# LPC43xx register map
File version: 10
CPU: CM4 r0p0, little endian, no MPU, no FPU, 3 interrupt priority bits
Registers are 32-bit, read-write, reset 0x0 unless marked. A register's access mark holds for its fields unless they carry their own. Offsets are from the block's base; [hi:lo] are bit positions; {n}, {i} and the like mark numbered series; 'fields as' and 'values as' point back to an identical list.

## RGU — Reset Generation Unit (RGU)
Base 0x40053000
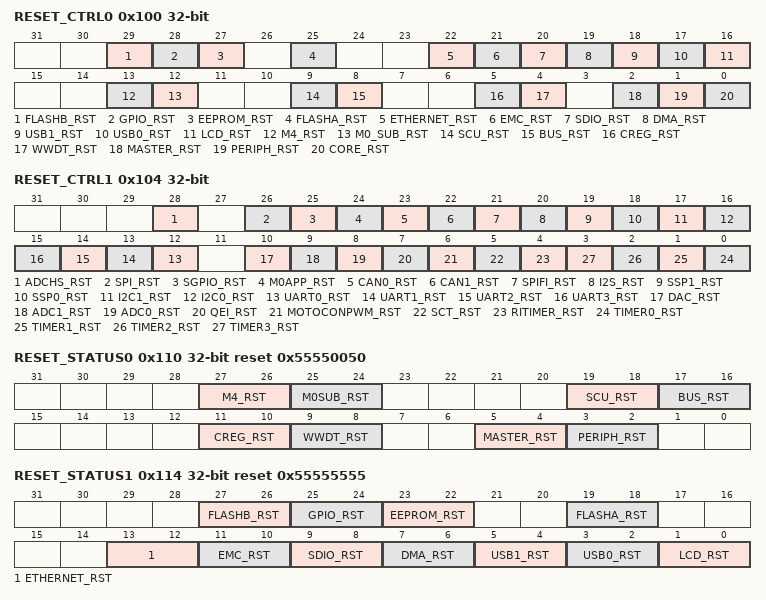
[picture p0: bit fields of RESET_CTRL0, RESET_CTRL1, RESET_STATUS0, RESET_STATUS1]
0x100 RESET_CTRL0 wo reset not defined — Reset control register 0
  [29] FLASHB_RST — Writing a one activates the reset. This bit is automatically cleared to 0 after one clock cycle.
  [28] GPIO_RST — Writing a one activates the reset. This bit is automatically cleared to 0 after one clock cycle.
  [27] EEPROM_RST — Writing a one activates the reset. This bit is automatically cleared to 0 after one clock cycle.
  [25] FLASHA_RST — Writing a one activates the reset. This bit is automatically cleared to 0 after one clock cycle.
  [22] ETHERNET_RST — Writing a one activates the reset. This bit is automatically cleared to 0 after one clock cycle.
  [21] EMC_RST — Writing a one activates the reset. This bit is automatically cleared to 0 after one clock cycle.
  [20] SDIO_RST — Writing a one activates the reset. This bit is automatically cleared to 0 after one clock cycle.
  [19] DMA_RST — Writing a one activates the reset. This bit is automatically cleared to 0 after one clock cycle.
  [18] USB1_RST — Writing a one activates the reset. This bit is automatically cleared to 0 after one clock cycle.
  [17] USB0_RST — Writing a one activates the reset. This bit is automatically cleared to 0 after one clock cycle.
  [16] LCD_RST — Writing a one activates the reset. This bit is automatically cleared to 0 after one clock cycle.
  [13] M4_RST — Writing a one activates the reset. This bit is automatically cleared to 0 after one clock cycle.
  [12] M0_SUB_RST — Writing a one activates the reset. Writing a 0 clears the reset. This bit must be cleared by software.
  [9] SCU_RST — Writing a one activates the reset. This bit is automatically cleared to 0 after one clock cycle.
  [8] BUS_RST — Writing a one activates the reset. This bit is automatically cleared to 0 after one clock cycle. Do not use during normal operation
  [5] CREG_RST — Writing a one to this bit has no effect.
  [4] WWDT_RST — Writing a one to this bit has no effect.
  [2] MASTER_RST — Writing a one activates the reset. This bit is automatically cleared to 0 after three clock cycles.
  [1] PERIPH_RST — Writing a one activates the reset. This bit is automatically cleared to 0 after three clock cycles.
  [0] CORE_RST — Writing a one activates the reset. This bit is automatically cleared to 0 after one clock cycle.
0x104 RESET_CTRL1 wo reset not defined — Reset control register 1
  [28] ADCHS_RST — Writing a one activates the reset. This bit is automatically cleared to 0 after one clock cycle.
  [26] SPI_RST — Writing a one activates the reset. This bit is automatically cleared to 0 after one clock cycle.
  [25] SGPIO_RST — Writing a one activates the reset. This bit is automatically cleared to 0 after one clock cycle.
  [24] M0APP_RST — Writing a one activates the reset. Writing a 0 clears the reset. This bit must be cleared by software.
  [23] CAN0_RST — Writing a one activates the reset. This bit is automatically cleared to 0 after one clock cycle.
  [22] CAN1_RST — Writing a one activates the reset. This bit is automatically cleared to 0 after one clock cycle.
  [21] SPIFI_RST — Writing a one activates the reset. This bit is automatically cleared to 0 after one clock cycle.
  [20] I2S_RST — Writing a one activates the reset. This bit is automatically cleared to 0 after one clock cycle.
  [19] SSP1_RST — Writing a one activates the reset. This bit is automatically cleared to 0 after one clock cycle.
  [18] SSP0_RST — Writing a one activates the reset. This bit is automatically cleared to 0 after one clock cycle.
  [17] I2C1_RST — Writing a one activates the reset. This bit is automatically cleared to 0 after one clock cycle.
  [16] I2C0_RST — Writing a one activates the reset. This bit is automatically cleared to 0 after one clock cycle.
  [n+12] UART{n}_RST (n=0..3) — Writing a one activates the reset. This bit is automatically cleared to 0 after one clock cycle.
  [10] DAC_RST — Writing a one activates the reset. This bit is automatically cleared to 0 after one clock cycle.
  [9] ADC1_RST — Writing a one activates the reset. This bit is automatically cleared to 0 after one clock cycle.
  [8] ADC0_RST — Writing a one activates the reset. This bit is automatically cleared to 0 after one clock cycle.
  [7] QEI_RST — Writing a one activates the reset. This bit is automatically cleared to 0 after one clock cycle.
  [6] MOTOCONPWM_RST — Writing a one activates the reset. This bit is automatically cleared to 0 after one clock cycle.
  [5] SCT_RST — Writing a one activates the reset. This bit is automatically cleared to 0 after one clock cycle.
  [4] RITIMER_RST — Writing a one activates the reset. This bit is automatically cleared to 0 after one clock cycle.
  [n] TIMER{n}_RST (n=0..3) — Writing a one activates the reset. This bit is automatically cleared to 0 after one clock cycle.
0x110 RESET_STATUS0 reset 0x55550050 — Reset status register 0
  [27:26] M4_RST — Status of the M4_RST reset generator output 00 = No reset activated 01 = Reset output activated by input to the reset generator 10 = Reserved 11 = Reset output activated by software write to RESET_CTRL register
  [25:24] M0SUB_RST — Status of the M0SUB_RST reset generator output 00 = No reset activated 01 = Reset output activated by input to the reset generator 10 = Reserved 11 = Reset output activated by software write to RESET_CTRL register
  [19:18] SCU_RST — Status of the SCU_RST reset generator output 00 = No reset activated 01 = Reset output activated by input to the reset generator 10 = Reserved 11 = Reset output activated by software write to RESET_CTRL register
  [17:16] BUS_RST — Status of the BUS_RST reset generator output 00 = No reset activated 01 = Reset output activated by input to the reset generator 10 = Reserved 11 = Reset output activated by software write to RESET_CTRL register
  [11:10] CREG_RST — Status of the CREG_RST reset generator output 00 = No reset activated 01 = Reset output activated by input to the reset generator 10 = Reserved 11 = Reserved
  [9:8] WWDT_RST — Status of the WWDT_RST reset generator output 00 = No reset activated 01 = Reset output activated by input to the reset generator 10 = Reserved 11 = Reserved
  [5:4] MASTER_RST — Status of the MASTER_RST reset generator output 00 = No reset activated 01 = Reset output activated by input to the reset generator - this reset is self-clearing 10 = Reserved 11 = Reset output activated by software write to RESET_CTRL register
  [3:2] PERIPH_RST — Status of the PERIPH_RST reset generator output 00 = No reset activated 01 = Reset output activated by input to the reset generator - this reset is self-clearing 10 = Reserved 11 = Reset output activated by software write to RESET_CTRL register
0x114 RESET_STATUS1 reset 0x55555555 — Reset status register 1
  [27:26] FLASHB_RST — Status of the FLASHB_RST reset generator output 00 = No reset activated 01 = Reset output activated by input to the reset generator 10 = Reserved 11 = Reset output activated by software write to RESET_CTRL register
  [25:24] GPIO_RST — Status of the GPIO_RST reset generator output 00 = No reset activated 01 = Reset output activated by input to the reset generator 10 = Reserved 11 = Reset output activated by software write to RESET_CTRL register
  [23:22] EEPROM_RST — Status of the EEPROM_RST reset generator output 00 = No reset activated 01 = Reset output activated by input to the reset generator 10 = Reserved 11 = Reset output activated by software write to RESET_CTRL register
  [19:18] FLASHA_RST — Status of the FLASHA_RST reset generator output 00 = No reset activated 01 = Reset output activated by input to the reset generator 10 = Reserved 11 = Reset output activated by software write to RESET_CTRL register
  [13:12] ETHERNET_RST — Status of the ETHERNET_RST reset generator output 00 = No reset activated 01 = Reset output activated by input to the reset generator 10 = Reserved 11 = Reset output activated by software write to RESET_CTRL register
  [11:10] EMC_RST — Status of the EMC_RST reset generator output 00 = No reset activated 01 = Reset output activated by input to the reset generator 10 = Reserved 11 = Reset output activated by software write to RESET_CTRL register
  [9:8] SDIO_RST — Status of the SDIO_RST reset generator output 00 = No reset activated 01 = Reset output activated by input to the reset generator 10 = Reserved 11 = Reset output activated by software write to RESET_CTRL register
  [7:6] DMA_RST — Status of the DMA_RST reset generator output 00 = No reset activated 01 = Reset output activated by input to the reset generator 10 = Reserved 11 = Reset output activated by software write to RESET_CTRL register
  [5:4] USB1_RST — Status of the USB1_RST reset generator output 00 = No reset activated 01 = Reset output activated by input to the reset generator 10 = Reserved 11 = Reset output activated by software write to RESET_CTRL register
  [3:2] USB0_RST — Status of the USB0_RST reset generator output 00 = No reset activated 01 = Reset output activated by input to the reset generator 10 = Reserved 11 = Reset output activated by software write to RESET_CTRL register
  [1:0] LCD_RST — Status of the LCD_RST reset generator output 00 = No reset activated 01 = Reset output activated by input to the reset generator 10 = Reserved 11 = Reset output activated by software write to RESET_CTRL register
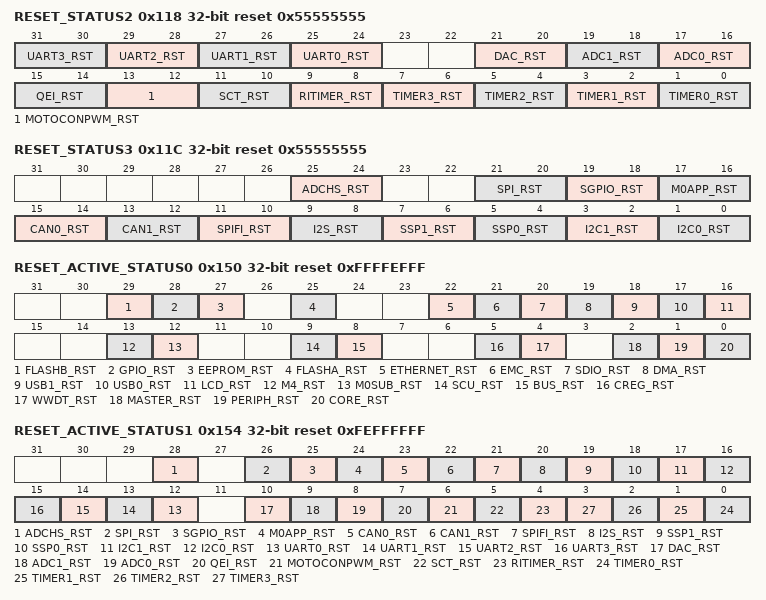
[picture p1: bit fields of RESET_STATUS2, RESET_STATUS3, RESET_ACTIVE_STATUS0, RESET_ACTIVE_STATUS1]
0x118 RESET_STATUS2 reset 0x55555555 — Reset status register 2
  [2n+25:2n+24] UART{n}_RST (n=0..3) — Status of the UART{n}_RST reset generator output 00 = No reset activated 01 = Reset output activated by input to the reset generator 10 = Reserved 11 = Reset output activated by software write to RESET_CTRL register
  [21:20] DAC_RST — Status of the DAC_RST reset generator output 00 = No reset activated 01 = Reset output activated by input to the reset generator 10 = Reserved 11 = Reset output activated by software write to RESET_CTRL register
  [19:18] ADC1_RST — Status of the ADC1_RST reset generator output 00 = No reset activated 01 = Reset output activated by input to the reset generator 10 = Reserved 11 = Reset output activated by software write to RESET_CTRL register
  [17:16] ADC0_RST — Status of the ADC0_RST reset generator output 00 = No reset activated 01 = Reset output activated by input to the reset generator 10 = Reserved 11 = Reset output activated by software write to RESET_CTRL register
  [15:14] QEI_RST — Status of the QEI_RST reset generator output 00 = No reset activated 01 = Reset output activated by input to the reset generator 10 = Reserved 11 = Reset output activated by software write to RESET_CTRL register
  [13:12] MOTOCONPWM_RST — Status of the MOTOCONPWM_RST reset generator output 00 = No reset activated 01 = Reset output activated by input to the reset generator 10 = Reserved 11 = Reset output activated by software write to RESET_CTRL register
  [11:10] SCT_RST — Status of the SCT_RST reset generator output 00 = No reset activated 01 = Reset output activated by input to the reset generator 10 = Reserved 11 = Reset output activated by software write to RESET_CTRL register
  [9:8] RITIMER_RST — Status of the RITIMER_RST reset generator output 00 = No reset activated 01 = Reset output activated by input to the reset generator 10 = Reserved 11 = Reset output activated by software write to RESET_CTRL register
  [2n+1:2n] TIMER{n}_RST (n=0..3) — Status of the TIMER{n}_RST reset generator output 00 = No reset activated 01 = Reset output activated by input to the reset generator 10 = Reserved 11 = Reset output activated by software write to RESET_CTRL register
0x11C RESET_STATUS3 reset 0x55555555 — Reset status register 3
  [25:24] ADCHS_RST — Status of the ADCHS_RST reset generator output 00 = No reset activated 01 = Reset output activated by input to the reset generator 10 = Reserved 11 = Reset output activated by software write to RESET_CTRL register
  [21:20] SPI_RST — Status of the SPI_RST reset generator output 00 = No reset activated 01 = Reset output activated by input to the reset generator 10 = Reserved 11 = Reset output activated by software write to RESET_CTRL register
  [19:18] SGPIO_RST — Status of the SGPIO_RST reset generator output 00 = No reset activated 01 = Reset output activated by input to the reset generator 10 = Reserved 11 = Reset output activated by software write to RESET_CTRL register
  [17:16] M0APP_RST — Status of the M0APP_RST reset generator output 00 = No reset activated 01 = Reset output activated by input to the reset generator 10 = Reserved 11 = Reset output activated by software write to RESET_CTRL register
  [15:14] CAN0_RST — Status of the CAN0_RST reset generator output 00 = No reset activated 01 = Reset output activated by input to the reset generator 10 = Reserved 11 = Reset output activated by software write to RESET_CTRL register
  [13:12] CAN1_RST — Status of the CAN1_RST reset generator output 00 = No reset activated 01 = Reset output activated by input to the reset generator 10 = Reserved 11 = Reset output activated by software write to RESET_CTRL register
  [11:10] SPIFI_RST — Status of the SPIFI_RST reset generator output 00 = No reset activated 01 = Reset output activated by input to the reset generator 10 = Reserved 11 = Reset output activated by software write to RESET_CTRL register
  [9:8] I2S_RST — Status of the I2S_RST reset generator output 00 = No reset activated 01 = Reset output activated by input to the reset generator 10 = Reserved 11 = Reset output activated by software write to RESET_CTRL register
  [7:6] SSP1_RST — Status of the SSP1_RST reset generator output 00 = No reset activated 01 = Reset output activated by input to the reset generator 10 = Reserved 11 = Reset output activated by software write to RESET_CTRL register
  [5:4] SSP0_RST — Status of the SSP0_RST reset generator output 00 = No reset activated 01 = Reset output activated by input to the reset generator 10 = Reserved 11 = Reset output activated by software write to RESET_CTRL register
  [3:2] I2C1_RST — Status of the I2C1_RST reset generator output 00 = No reset activated 01 = Reset output activated by input to the reset generator 10 = Reserved 11 = Reset output activated by software write to RESET_CTRL register
  [1:0] I2C0_RST — Status of the I2C0_RST reset generator output 00 = No reset activated 01 = Reset output activated by input to the reset generator 10 = Reserved 11 = Reset output activated by software write to RESET_CTRL register
0x150 RESET_ACTIVE_STATUS0 ro reset 0xFFFFEFFF — Reset active status register 0
  [29] FLASHB_RST — Current status of the FLASHB_RST 0 = Reset asserted 1 = No reset
  [28] GPIO_RST — Current status of the GPIO_RST 0 = Reset asserted 1 = No reset
  [27] EEPROM_RST — Current status of the EEPROM_RST 0 = Reset asserted 1 = No reset
  [25] FLASHA_RST — Current status of the FLASHA_RST 0 = Reset asserted 1 = No reset
  [22] ETHERNET_RST — Current status of the ETHERNET_RST 0 = Reset asserted 1 = No reset
  [21] EMC_RST — Current status of the EMC_RST 0 = Reset asserted 1 = No reset
  [20] SDIO_RST — Current status of the SDIO_RST 0 = Reset asserted 1 = No reset
  [19] DMA_RST — Current status of the DMA_RST 0 = Reset asserted 1 = No reset
  [18] USB1_RST — Current status of the USB1_RST 0 = Reset asserted 1 = No reset
  [17] USB0_RST — Current status of the USB0_RST 0 = Reset asserted 1 = No reset
  [16] LCD_RST — Current status of the LCD_RST 0 = Reset asserted 1 = No reset
  [13] M4_RST — Current status of the M4_RST 0 = Reset asserted 1 = No reset
  [12] M0SUB_RST — Current status of the M0SUB_RST 0 = Reset asserted 1 = No reset
  [9] SCU_RST — Current status of the SCU_RST 0 = Reset asserted 1 = No reset
  [8] BUS_RST — Current status of the BUS_RST 0 = Reset asserted 1 = No reset
  [5] CREG_RST — Current status of the CREG_RST 0 = Reset asserted 1 = No reset
  [4] WWDT_RST — Current status of the WWDT_RS 0 = Reset asserted 1 = No reset
  [2] MASTER_RST — Current status of the MASTER_RST 0 = Reset asserted 1 = No reset
  [1] PERIPH_RST — Current status of the PERIPH_RST 0 = Reset asserted 1 = No reset
  [0] CORE_RST — Current status of the CORE_RST 0 = Reset asserted 1 = No reset
0x154 RESET_ACTIVE_STATUS1 ro reset 0xFEFFFFFF — Reset active status register 1
  [28] ADCHS_RST — Current status of the ADCHS_RST 0 = Reset asserted 1 = No reset
  [26] SPI_RST — Current status of the SPI_RST 0 = Reset asserted 1 = No reset
  [25] SGPIO_RST — Current status of the SGPIO_RST 0 = Reset asserted 1 = No reset
  [24] M0APP_RST — Current status of the M0APP_RST 0 = Reset asserted 1 = No reset
  [23] CAN0_RST — Current status of the CAN0_RST 0 = Reset asserted 1 = No reset
  [22] CAN1_RST — Current status of the CAN1_RST 0 = Reset asserted 1 = No reset
  [21] SPIFI_RST — Current status of the SPIFI_RST 0 = Reset asserted 1 = No reset
  [20] I2S_RST — Current status of the I2S_RST 0 = Reset asserted 1 = No reset
  [19] SSP1_RST — Current status of the SSP1_RST 0 = Reset asserted 1 = No reset
  [18] SSP0_RST — Current status of the SSP0_RST 0 = Reset asserted 1 = No reset
  [17] I2C1_RST — Current status of the I2C1_RST 0 = Reset asserted 1 = No reset
  [16] I2C0_RST — Current status of the I2C0_RST 0 = Reset asserted 1 = No reset
  [n+12] UART{n}_RST (n=0..3) — Current status of the UART{n}_RST 0 = Reset asserted 1 = No reset
  [10] DAC_RST — Current status of the DAC_RST 0 = Reset asserted 1 = No reset
  [9] ADC1_RST — Current status of the ADC1_RST 0 = Reset asserted 1 = No reset
  [8] ADC0_RST — Current status of the ADC0_RST 0 = Reset asserted 1 = No reset
  [7] QEI_RST — Current status of the QEI_RST 0 = Reset asserted 1 = No reset
  [6] MOTOCONPWM_RST — Current status of the MOTOCONPWM_RST 0 = Reset asserted 1 = No reset
  [5] SCT_RST — Current status of the SCT_RST 0 = Reset asserted 1 = No reset
  [4] RITIMER_RST — Current status of the RITIMER_RST 0 = Reset asserted 1 = No reset
  [n] TIMER{n}_RST (n=0..3) — Current status of the TIMER{n}_RST 0 = Reset asserted 1 = No reset
0x404 RESET_EXT_STAT1 — Reset external status register 1 for PERIPH_RST
  [1] CORE_RESET — Reset activated by CORE_RST output. Write 0 to clear. 0 = Reset not activated 1 = Reset activated
0x408 RESET_EXT_STAT2 reset 0x4 — Reset external status register 2 for MASTER_RST
  [2] PERIPHERAL_RESET — Reset activated by PERIPHERAL_RST output. Write 0 to clear. 0 = Reset not activated 1 = Reset activated
0x414 RESET_EXT_STAT5 — Reset external status register 5 for CREG_RST
  fields as RESET_EXT_STAT1
0x420 RESET_EXT_STAT8 reset 0x4 — Reset external status register
  fields as RESET_EXT_STAT2
0x424 RESET_EXT_STAT9 reset 0x4 — Reset external status register
  fields as RESET_EXT_STAT2
0x430 RESET_EXT_STAT12 reset 0x8 — Reset external status register
  [3] MASTER_RESET — Reset activated by MASTER_RST output. Write 0 to clear. 0 = Reset not activated 1 = Reset activated
0x434 RESET_EXT_STAT13 reset 0x8 — Reset external status register
  fields as RESET_EXT_STAT12
{0x400+4i} RESET_EXT_STAT{i} reset 0x8 (i=16..22) — Reset external status register
  fields as RESET_EXT_STAT12
0x464 RESET_EXT_STAT25 reset 0x4 — Reset external status register
  fields as RESET_EXT_STAT12
0x46C RESET_EXT_STAT27 reset 0x4 — Reset external status register
  fields as RESET_EXT_STAT12
0x470 RESET_EXT_STAT28 reset 0x4 — Reset external status register
  fields as RESET_EXT_STAT2
0x474 RESET_EXT_STAT29 reset 0x4 — Reset external status register
  fields as RESET_EXT_STAT12
{0x400+4i} RESET_EXT_STAT{i} reset 0x4 (i=32..42) — Reset external status register
  fields as RESET_EXT_STAT2
{0x400+4i} RESET_EXT_STAT{i} reset 0x4 (i=44..55) — Reset external status register
  fields as RESET_EXT_STAT2
0x4E0 RESET_EXT_STAT56 reset 0x8 — Reset external status register
  fields as RESET_EXT_STAT2
0x4E4 RESET_EXT_STAT57 reset 0x4 — Reset external status register
  fields as RESET_EXT_STAT2
0x4E8 RESET_EXT_STAT58 reset 0x4 — Reset external status register
  fields as RESET_EXT_STAT2
0x4F0 RESET_EXT_STAT60 reset 0x4 — Reset external status register
  fields as RESET_EXT_STAT2
